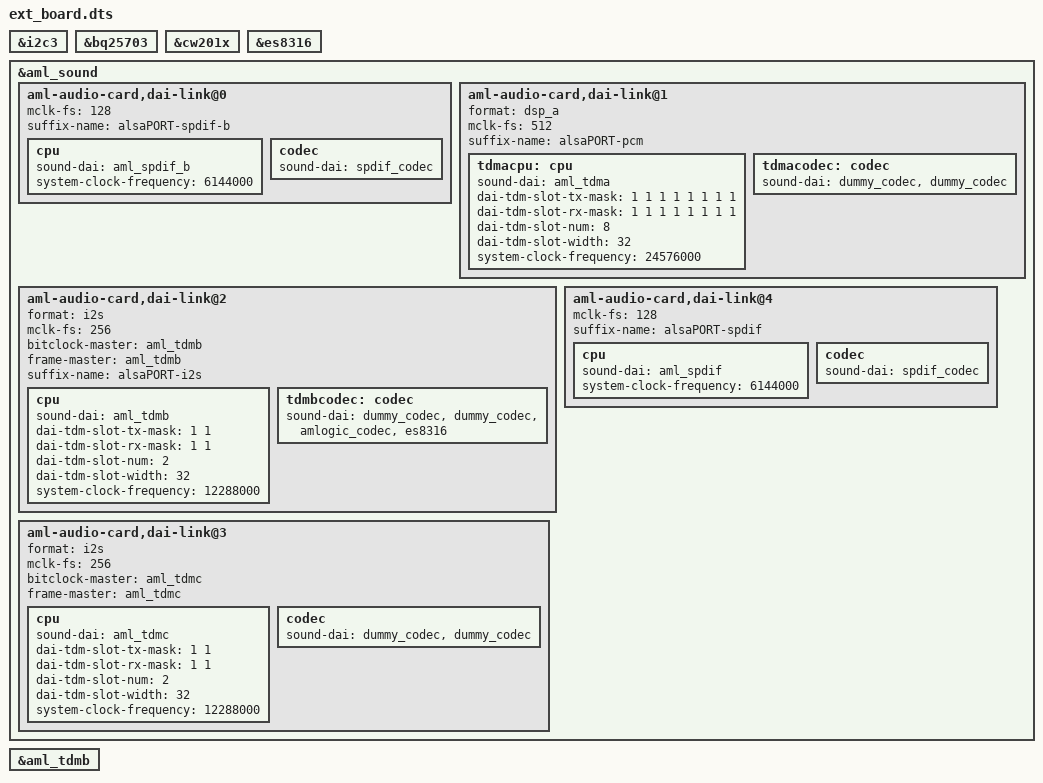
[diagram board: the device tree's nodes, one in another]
/dts-v1/;
/plugin/;

#include <dt-bindings/interrupt-controller/arm-gic.h>
#include <dt-bindings/gpio/meson-g12a-gpio.h>
#include <dt-bindings/gpio/gpio.h>

/ {
    fragment@0 {
        target = <&i2c3>;

        __overlay__ {
            status = "okay";
		};
	};

	fragment@1 {
		target = <&bq25703>;

		__overlay__ {
			status = "okay";
		};
	};

	fragment@2 {
		target = <&cw201x>;

		__overlay__ {
			status = "okay";
		};
	};

	fragment@3 {
		target = <&es8316>;

		__overlay__ {
			status = "okay";
		};
	};

	fragment@4 {
		target = <&aml_sound>;

		__overlay__ {
			aml-audio-card,dai-link@0 {
				mclk-fs = <128>;
				/* suffix-name, sync with android audio hal
				 * what's the dai link used for
				 */
				suffix-name = "alsaPORT-spdif-b";
				cpu {
					sound-dai = <&aml_spdif_b>;
					system-clock-frequency = <6144000>;
				};
				codec {
					sound-dai = <&spdif_codec>;
				};
			};

			aml-audio-card,dai-link@1 {
				format = "dsp_a";
				mclk-fs = <512>;
				//continuous-clock;
				//bitclock-inversion;
				//frame-inversion;
				//bitclock-master = <&tdmacodec>;
				//frame-master = <&tdmacodec>;
				/* suffix-name, sync with android audio hal
				 * what's the dai link used for
				 */
				suffix-name = "alsaPORT-pcm";
				tdmacpu: cpu {
			 				 sound-dai = <&aml_tdma>;
			 				 dai-tdm-slot-tx-mask =
	 							 <1 1 1 1 1 1 1 1>;
			 				 dai-tdm-slot-rx-mask =
	 							 <1 1 1 1 1 1 1 1>;
			 				 dai-tdm-slot-num = <8>;
			 				 dai-tdm-slot-width = <32>;
			 				 system-clock-frequency = <24576000>;
			 			 };
				tdmacodec: codec {
			   		sound-dai = <&dummy_codec &dummy_codec>;
				};
			};

			aml-audio-card,dai-link@2 {
				format = "i2s";
				mclk-fs = <256>;
				//continuous-clock;
				//bitclock-inversion;
				//frame-inversion;
				bitclock-master = <&aml_tdmb>;
				frame-master = <&aml_tdmb>;
				//bitclock-master = <&tdmbcodec>;
				//frame-master = <&tdmbcodec>;
				/* suffix-name, sync with android audio hal
				 * what's the dai link used for
				 */
				suffix-name = "alsaPORT-i2s";
				cpu {
					sound-dai = <&aml_tdmb>;
					dai-tdm-slot-tx-mask = <1 1>;
					dai-tdm-slot-rx-mask = <1 1>;
					dai-tdm-slot-num = <2>;
					dai-tdm-slot-width = <32>;
					system-clock-frequency = <12288000>;
				};
				tdmbcodec: codec {
			   		sound-dai = <&dummy_codec &dummy_codec
						&amlogic_codec &es8316>;
			   	};
			};
			aml-audio-card,dai-link@3 {
   				format = "i2s";
   				mclk-fs = <256>;
   				//continuous-clock;
   				//bitclock-inversion;
   				//frame-inversion;
   				bitclock-master = <&aml_tdmc>;
   				frame-master = <&aml_tdmc>;
   				/* suffix-name, sync with android audio hal
				 * what's the dai link used for
				 */
   				//suffix-name = "alsaPORT-tdm";
   				cpu {
   					sound-dai = <&aml_tdmc>;
   					dai-tdm-slot-tx-mask = <1 1>;
   					dai-tdm-slot-rx-mask = <1 1>;
   					dai-tdm-slot-num = <2>;
   					dai-tdm-slot-width = <32>;
   					system-clock-frequency = <12288000>;
   				};
   				codec {
   					sound-dai = <&dummy_codec &dummy_codec>;
   				};
   			};

   			aml-audio-card,dai-link@4 {
   				mclk-fs = <128>;
   				/* suffix-name, sync with android audio hal
				 * what's the dai link used for
				 */
   				suffix-name = "alsaPORT-spdif";
   				cpu {
   					sound-dai = <&aml_spdif>;
   					system-clock-frequency = <6144000>;
   				};
   				codec {
   					sound-dai = <&spdif_codec>;
   				};
   			};
   		};
   	};

   	fragment@5 {
   		target = <&aml_tdmb>;

   		__overlay__ {
   			status = "okay";
   		};
   	};
};

